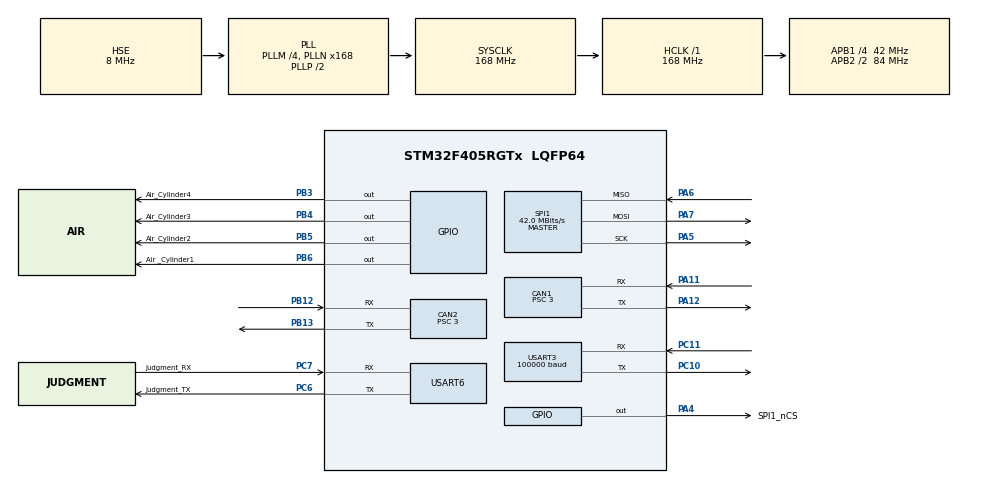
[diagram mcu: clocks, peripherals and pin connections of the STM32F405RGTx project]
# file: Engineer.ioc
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CAN1.ABOM=ENABLE
CAN1.BS1=CAN_BS1_9TQ
CAN1.BS2=CAN_BS2_4TQ
CAN1.CalculateTimeQuantum=71.42857142857143
CAN1.Prescaler=3
CAN2.ABOM=ENABLE
CAN2.BS1=CAN_BS1_9TQ
CAN2.BS2=CAN_BS2_4TQ
CAN2.CalculateTimeQuantum=71.42857142857143
CAN2.Prescaler=3
Dma.Request0=USART6_RX
Dma.Request1=USART6_TX
Dma.Request2=USART3_RX
Dma.USART3_RX.2.Direction=DMA_PERIPH_TO_MEMORY
Dma.USART3_RX.2.FIFOMode=DMA_FIFOMODE_DISABLE
Dma.USART3_RX.2.Instance=DMA1_Stream1
Dma.USART3_RX.2.MemDataAlignment=DMA_MDATAALIGN_BYTE
Dma.USART3_RX.2.MemInc=DMA_MINC_ENABLE
Dma.USART3_RX.2.Mode=DMA_NORMAL
Dma.USART3_RX.2.PeriphDataAlignment=DMA_PDATAALIGN_BYTE
Dma.USART3_RX.2.PeriphInc=DMA_PINC_DISABLE
Dma.USART3_RX.2.Priority=DMA_PRIORITY_LOW
Dma.USART6_RX.0.Direction=DMA_PERIPH_TO_MEMORY
Dma.USART6_RX.0.FIFOMode=DMA_FIFOMODE_DISABLE
Dma.USART6_RX.0.Instance=DMA2_Stream1
Dma.USART6_RX.0.MemDataAlignment=DMA_MDATAALIGN_BYTE
Dma.USART6_RX.0.MemInc=DMA_MINC_ENABLE
Dma.USART6_RX.0.Mode=DMA_NORMAL
Dma.USART6_RX.0.PeriphDataAlignment=DMA_PDATAALIGN_BYTE
Dma.USART6_RX.0.PeriphInc=DMA_PINC_DISABLE
Dma.USART6_RX.0.Priority=DMA_PRIORITY_LOW
Dma.USART6_TX.1.Direction=DMA_MEMORY_TO_PERIPH
Dma.USART6_TX.1.FIFOMode=DMA_FIFOMODE_DISABLE
Dma.USART6_TX.1.Instance=DMA2_Stream6
Dma.USART6_TX.1.MemDataAlignment=DMA_MDATAALIGN_BYTE
Dma.USART6_TX.1.MemInc=DMA_MINC_DISABLE
Dma.USART6_TX.1.Mode=DMA_NORMAL
Dma.USART6_TX.1.PeriphDataAlignment=DMA_PDATAALIGN_BYTE
Dma.USART6_TX.1.PeriphInc=DMA_PINC_DISABLE
Dma.USART6_TX.1.Priority=DMA_PRIORITY_LOW
FREERTOS.INCLUDE_vTaskDelayUntil=1
FREERTOS.Tasks01=Create_Task,0,128,CreateTask,Default,NULL,Dynamic,NULL,NULL
Mcu.Family=STM32F4
Mcu.Name=STM32F405RGTx
Mcu.Package=LQFP64
NVIC.CAN1_RX0_IRQn=true\:5\:0\:false\:false\:true\:true\:true\:true
NVIC.CAN2_RX0_IRQn=true\:5\:0\:false\:false\:true\:true\:true\:true
NVIC.DMA1_Stream1_IRQn=true\:5\:0\:false\:false\:true\:true\:false\:true
NVIC.DMA2_Stream1_IRQn=true\:5\:0\:false\:false\:true\:true\:false\:true
NVIC.DMA2_Stream6_IRQn=true\:5\:0\:false\:false\:true\:true\:false\:true
NVIC.PriorityGroup=NVIC_PRIORITYGROUP_4
NVIC.TIM8_TRG_COM_TIM14_IRQn=true\:0\:0\:false\:false\:true\:false\:false\:true
NVIC.TimeBase=TIM8_TRG_COM_TIM14_IRQn
NVIC.TimeBaseIP=TIM14
NVIC.USART3_IRQn=true\:5\:0\:false\:false\:true\:true\:true\:true
NVIC.USART6_IRQn=true\:5\:0\:false\:false\:true\:true\:true\:true
PA11.Mode=Master
PA11.Signal=CAN1_RX
PA12.Mode=Master
PA12.Signal=CAN1_TX
PA13.Mode=Serial_Wire
PA13.Signal=SYS_JTMS-SWDIO
PA14.Mode=Serial_Wire
PA14.Signal=SYS_JTCK-SWCLK
PA4.GPIO_Label=SPI1_nCS
PA4.Signal=GPIO_Output
PA5.Mode=Full_Duplex_Master
PA5.Signal=SPI1_SCK
PA6.Mode=Full_Duplex_Master
PA6.Signal=SPI1_MISO
PA7.Mode=Full_Duplex_Master
PA7.Signal=SPI1_MOSI
PB12.Mode=Slave
PB12.Signal=CAN2_RX
PB13.Mode=Slave
PB13.Signal=CAN2_TX
PB3.GPIO_Label=Air_Cylinder4
PB3.GPIO_PuPd=GPIO_PULLDOWN
PB3.Signal=GPIO_Output
PB4.GPIO_Label=Air_Cylinder3
PB4.GPIO_ModeDefaultOutputPP=GPIO_MODE_OUTPUT_PP
PB4.GPIO_PuPd=GPIO_PULLDOWN
PB4.Signal=GPIO_Output
PB5.GPIO_Label=Air_Cylinder2
PB5.GPIO_PuPd=GPIO_PULLDOWN
PB5.Signal=GPIO_Output
PB6.GPIO_Label=Air _Cylinder1
PB6.GPIO_PuPd=GPIO_PULLDOWN
PB6.Signal=GPIO_Output
PC10.Mode=Asynchronous
PC10.Signal=USART3_TX
PC11.Mode=Asynchronous
PC11.Signal=USART3_RX
PC6.GPIO_Label=Judgment_TX
PC6.Mode=Asynchronous
PC6.Signal=USART6_TX
PC7.GPIO_Label=Judgment_RX
PC7.Mode=Asynchronous
PC7.Signal=USART6_RX
PH0-OSC_IN.Mode=HSE-External-Oscillator
PH0-OSC_IN.Signal=RCC_OSC_IN
PH1-OSC_OUT.Mode=HSE-External-Oscillator
PH1-OSC_OUT.Signal=RCC_OSC_OUT
ProjectManager.HeapSize=0x200
ProjectManager.StackSize=0x400
ProjectManager.TargetToolchain=MDK-ARM V5
RCC.48MHZClocksFreq_Value=84000000
RCC.AHBFreq_Value=168000000
RCC.APB1CLKDivider=RCC_HCLK_DIV4
RCC.APB1Freq_Value=42000000
RCC.APB1TimFreq_Value=84000000
RCC.APB2CLKDivider=RCC_HCLK_DIV2
RCC.APB2Freq_Value=84000000
RCC.APB2TimFreq_Value=168000000
RCC.CortexFreq_Value=168000000
RCC.HCLKFreq_Value=168000000
RCC.HSE_VALUE=8000000
RCC.HSI_VALUE=16000000
RCC.LSE_VALUE=32768
RCC.PLLM=4
RCC.PLLN=168
RCC.PLLSourceVirtual=RCC_PLLSOURCE_HSE
RCC.SYSCLKFreq_VALUE=168000000
RCC.SYSCLKSource=RCC_SYSCLKSOURCE_PLLCLK
RCC.VCOOutputFreq_Value=336000000
SPI1.BaudRatePrescaler=SPI_BAUDRATEPRESCALER_2
SPI1.CalculateBaudRate=42.0 MBits/s
SPI1.Direction=SPI_DIRECTION_2LINES
SPI1.Mode=SPI_MODE_MASTER
SPI1.VirtualType=VM_MASTER
USART3.BaudRate=100000
USART3.Parity=PARITY_EVEN
USART3.VirtualMode=VM_ASYNC
USART3.WordLength=WORDLENGTH_9B
USART6.VirtualMode=VM_ASYNC
VP_FREERTOS_VS_CMSIS_V1.Mode=CMSIS_V1
VP_SYS_VS_tim14.Mode=TIM14
board=custom

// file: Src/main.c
/* USER CODE BEGIN Header */
/**
  ******************************************************************************
  * @file           : main.c
  * @brief          : Main program body
  ******************************************************************************
  * @attention
  *
  * <h2><center>&copy; Copyright (c) 2019 STMicroelectronics.
  * All rights reserved.</center></h2>
  *
  * This software component is licensed by ST under Ultimate Liberty license
  * SLA0044, the "License"; You may not use this file except in compliance with
  * the License. You may obtain a copy of the License at:
  *                             www.st.com/SLA0044
  *
  ******************************************************************************
  */
/* USER CODE END Header */

#include "main.h"
#include "cmsis_os.h"
#include "can.h"
#include "dma.h"
#include "spi.h"
#include "usart.h"
#include "gpio.h"

/* USER CODE BEGIN Includes */
#include "my_bsp.h"
#include "my_app.h"
#include "my_task.h"
/* USER CODE END Includes */

void SystemClock_Config(void);
void MX_FREERTOS_Init(void);

int main(void)
{

  /* MCU Configuration--------------------------------------------------------*/

  /* Reset of all peripherals, Initializes the Flash interface and the Systick. */
  HAL_Init();

  /* Configure the system clock */
  SystemClock_Config();

  /* Initialize all configured peripherals */
  MX_GPIO_Init();
  MX_DMA_Init();
  MX_CAN1_Init();
  MX_SPI1_Init();
  MX_USART3_UART_Init();
  MX_USART6_UART_Init();
  MX_CAN2_Init();

  /* USER CODE BEGIN 2 */
	bsp_can_Init();
  /* USER CODE END 2 */

  /* Call init function for freertos objects (in freertos.c) */
//  MX_FREERTOS_Init();

  /* Start scheduler */
//  osKernelStart();

  /* We should never get here as control is now taken by the scheduler */

  /* Infinite loop */
  while (1)
  {

  }
}

void SystemClock_Config(void)
{
  RCC_OscInitTypeDef RCC_OscInitStruct = {0};
  RCC_ClkInitTypeDef RCC_ClkInitStruct = {0};

  /** Configure the main internal regulator output voltage
  */
  __HAL_RCC_PWR_CLK_ENABLE();
  __HAL_PWR_VOLTAGESCALING_CONFIG(PWR_REGULATOR_VOLTAGE_SCALE1);
  /** Initializes the CPU, AHB and APB busses clocks
  */
  RCC_OscInitStruct.OscillatorType = RCC_OSCILLATORTYPE_HSE;
  RCC_OscInitStruct.HSEState = RCC_HSE_ON;
  RCC_OscInitStruct.PLL.PLLState = RCC_PLL_ON;
  RCC_OscInitStruct.PLL.PLLSource = RCC_PLLSOURCE_HSE;
  RCC_OscInitStruct.PLL.PLLM = 4;
  RCC_OscInitStruct.PLL.PLLN = 168;
  RCC_OscInitStruct.PLL.PLLP = RCC_PLLP_DIV2;
  RCC_OscInitStruct.PLL.PLLQ = 4;
  if (HAL_RCC_OscConfig(&RCC_OscInitStruct) != HAL_OK)
  {
    Error_Handler();
  }
  /** Initializes the CPU, AHB and APB busses clocks
  */
  RCC_ClkInitStruct.ClockType = RCC_CLOCKTYPE_HCLK|RCC_CLOCKTYPE_SYSCLK
                              |RCC_CLOCKTYPE_PCLK1|RCC_CLOCKTYPE_PCLK2;
  RCC_ClkInitStruct.SYSCLKSource = RCC_SYSCLKSOURCE_PLLCLK;
  RCC_ClkInitStruct.AHBCLKDivider = RCC_SYSCLK_DIV1;
  RCC_ClkInitStruct.APB1CLKDivider = RCC_HCLK_DIV4;
  RCC_ClkInitStruct.APB2CLKDivider = RCC_HCLK_DIV2;

  if (HAL_RCC_ClockConfig(&RCC_ClkInitStruct, FLASH_LATENCY_5) != HAL_OK)
  {
    Error_Handler();
  }
}

void HAL_TIM_PeriodElapsedCallback(TIM_HandleTypeDef *htim)
{
  if (htim->Instance == TIM14) {
    HAL_IncTick();
  }
}

void Error_Handler(void)
{
}

/************************ (C) COPYRIGHT STMicroelectronics *****END OF FILE****/
